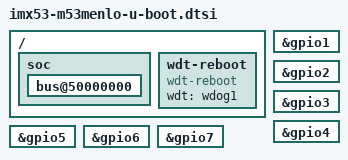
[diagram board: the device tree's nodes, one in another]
// SPDX-License-Identifier: (GPL-2.0+ OR MIT)
/*
 * Copyright (C) 2019 Marek Vasut <marex@denx.de>
 */

/ {
	soc {
		bootph-all;

		bus@50000000 {
			bootph-all;
		};
	};

	wdt-reboot {
		compatible = "wdt-reboot";
		wdt = <&wdog1>;
	};
};

&gpio1 {
	bootph-all;
};

&gpio2 {
	bootph-all;
};

&gpio3 {
	bootph-all;
};

&gpio4 {
	bootph-all;
};

&gpio5 {
	bootph-all;
};

&gpio6 {
	bootph-all;
};

&gpio7 {
	bootph-all;
};
